# RP2350 register map
Vendor: Raspberry Pi; File version: 0.1
CPU: CM33 r1p0, little endian, MPU, FPU, VTOR, 4 interrupt priority bits, 54 interrupts, 8 SAU regions
Registers are 32-bit, read-write, reset 0x0 unless marked. A register's access mark holds for its fields unless they carry their own. Offsets are from the block's base; [hi:lo] are bit positions.

## ACCESSCTRL_APBS (part 2 of 2) — Hardware access control registers
Base 0x40060000
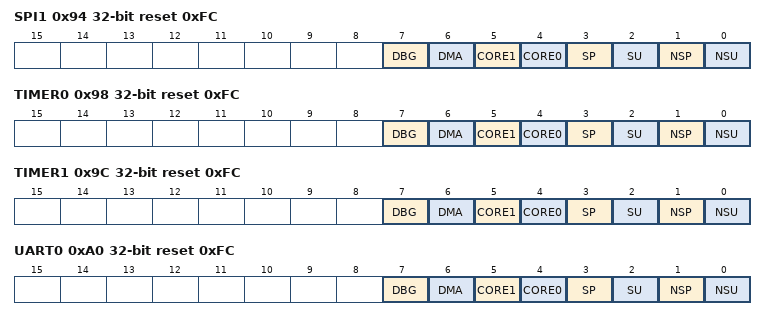
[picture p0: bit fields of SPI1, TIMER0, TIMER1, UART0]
0x94 SPI1 reset 0xFC — Control whether debugger, DMA, core 0 and core 1 can access SPI1, and at what security/privilege levels they can do so. . Defaults to Secure access from any master. . This register is writable only from a Secure, Privileged processor or debugger, with the exception of the NSU bit, which becomes NonSecure-Privileged-writable when the NSP bit is set.
  [7] DBG — If 1, SPI1 can be accessed by the debugger, at security/privilege levels permitted by SP/NSP/SU/NSU in this register.
  [6] DMA — If 1, SPI1 can be accessed by the DMA, at security/privilege levels permitted by SP/NSP/SU/NSU in this register.
  [5] CORE1 — If 1, SPI1 can be accessed by core 1, at security/privilege levels permitted by SP/NSP/SU/NSU in this register.
  [4] CORE0 — If 1, SPI1 can be accessed by core 0, at security/privilege levels permitted by SP/NSP/SU/NSU in this register.
  [3] SP — If 1, SPI1 can be accessed from a Secure, Privileged context.
  [2] SU — If 1, and SP is also set, SPI1 can be accessed from a Secure, Unprivileged context.
  [1] NSP — If 1, SPI1 can be accessed from a NonSecure, Privileged context.
  [0] NSU — If 1, and NSP is also set, SPI1 can be accessed from a NonSecure, Unprivileged context. . This bit is writable from a NonSecure, Privileged context, if and only if the NSP bit is set.
0x98 TIMER0 reset 0xFC — Control whether debugger, DMA, core 0 and core 1 can access TIMER0, and at what security/privilege levels they can do so. . Defaults to Secure access from any master. . This register is writable only from a Secure, Privileged processor or debugger, with the exception of the NSU bit, which becomes NonSecure-Privileged-writable when the NSP bit is set.
  [7] DBG — If 1, TIMER0 can be accessed by the debugger, at security/privilege levels permitted by SP/NSP/SU/NSU in this register.
  [6] DMA — If 1, TIMER0 can be accessed by the DMA, at security/privilege levels permitted by SP/NSP/SU/NSU in this register.
  [5] CORE1 — If 1, TIMER0 can be accessed by core 1, at security/privilege levels permitted by SP/NSP/SU/NSU in this register.
  [4] CORE0 — If 1, TIMER0 can be accessed by core 0, at security/privilege levels permitted by SP/NSP/SU/NSU in this register.
  [3] SP — If 1, TIMER0 can be accessed from a Secure, Privileged context.
  [2] SU — If 1, and SP is also set, TIMER0 can be accessed from a Secure, Unprivileged context.
  [1] NSP — If 1, TIMER0 can be accessed from a NonSecure, Privileged context.
  [0] NSU — If 1, and NSP is also set, TIMER0 can be accessed from a NonSecure, Unprivileged context. . This bit is writable from a NonSecure, Privileged context, if and only if the NSP bit is set.
0x9C TIMER1 reset 0xFC — Control whether debugger, DMA, core 0 and core 1 can access TIMER1, and at what security/privilege levels they can do so. . Defaults to Secure access from any master. . This register is writable only from a Secure, Privileged processor or debugger, with the exception of the NSU bit, which becomes NonSecure-Privileged-writable when the NSP bit is set.
  [7] DBG — If 1, TIMER1 can be accessed by the debugger, at security/privilege levels permitted by SP/NSP/SU/NSU in this register.
  [6] DMA — If 1, TIMER1 can be accessed by the DMA, at security/privilege levels permitted by SP/NSP/SU/NSU in this register.
  [5] CORE1 — If 1, TIMER1 can be accessed by core 1, at security/privilege levels permitted by SP/NSP/SU/NSU in this register.
  [4] CORE0 — If 1, TIMER1 can be accessed by core 0, at security/privilege levels permitted by SP/NSP/SU/NSU in this register.
  [3] SP — If 1, TIMER1 can be accessed from a Secure, Privileged context.
  [2] SU — If 1, and SP is also set, TIMER1 can be accessed from a Secure, Unprivileged context.
  [1] NSP — If 1, TIMER1 can be accessed from a NonSecure, Privileged context.
  [0] NSU — If 1, and NSP is also set, TIMER1 can be accessed from a NonSecure, Unprivileged context. . This bit is writable from a NonSecure, Privileged context, if and only if the NSP bit is set.
0xA0 UART0 reset 0xFC — Control whether debugger, DMA, core 0 and core 1 can access UART0, and at what security/privilege levels they can do so. . Defaults to Secure access from any master. . This register is writable only from a Secure, Privileged processor or debugger, with the exception of the NSU bit, which becomes NonSecure-Privileged-writable when the NSP bit is set.
  [7] DBG — If 1, UART0 can be accessed by the debugger, at security/privilege levels permitted by SP/NSP/SU/NSU in this register.
  [6] DMA — If 1, UART0 can be accessed by the DMA, at security/privilege levels permitted by SP/NSP/SU/NSU in this register.
  [5] CORE1 — If 1, UART0 can be accessed by core 1, at security/privilege levels permitted by SP/NSP/SU/NSU in this register.
  [4] CORE0 — If 1, UART0 can be accessed by core 0, at security/privilege levels permitted by SP/NSP/SU/NSU in this register.
  [3] SP — If 1, UART0 can be accessed from a Secure, Privileged context.
  [2] SU — If 1, and SP is also set, UART0 can be accessed from a Secure, Unprivileged context.
  [1] NSP — If 1, UART0 can be accessed from a NonSecure, Privileged context.
  [0] NSU — If 1, and NSP is also set, UART0 can be accessed from a NonSecure, Unprivileged context. . This bit is writable from a NonSecure, Privileged context, if and only if the NSP bit is set.
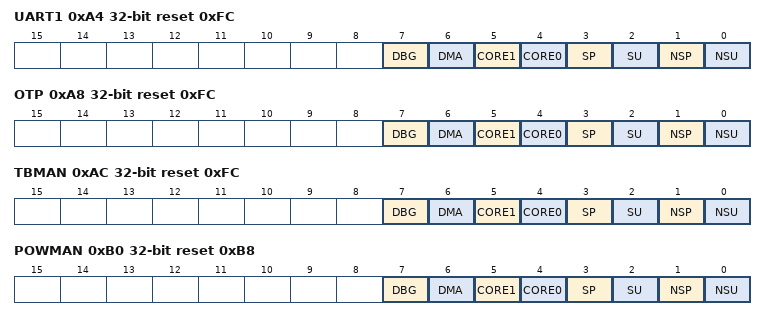
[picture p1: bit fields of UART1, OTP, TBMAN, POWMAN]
0xA4 UART1 reset 0xFC — Control whether debugger, DMA, core 0 and core 1 can access UART1, and at what security/privilege levels they can do so. . Defaults to Secure access from any master. . This register is writable only from a Secure, Privileged processor or debugger, with the exception of the NSU bit, which becomes NonSecure-Privileged-writable when the NSP bit is set.
  [7] DBG — If 1, UART1 can be accessed by the debugger, at security/privilege levels permitted by SP/NSP/SU/NSU in this register.
  [6] DMA — If 1, UART1 can be accessed by the DMA, at security/privilege levels permitted by SP/NSP/SU/NSU in this register.
  [5] CORE1 — If 1, UART1 can be accessed by core 1, at security/privilege levels permitted by SP/NSP/SU/NSU in this register.
  [4] CORE0 — If 1, UART1 can be accessed by core 0, at security/privilege levels permitted by SP/NSP/SU/NSU in this register.
  [3] SP — If 1, UART1 can be accessed from a Secure, Privileged context.
  [2] SU — If 1, and SP is also set, UART1 can be accessed from a Secure, Unprivileged context.
  [1] NSP — If 1, UART1 can be accessed from a NonSecure, Privileged context.
  [0] NSU — If 1, and NSP is also set, UART1 can be accessed from a NonSecure, Unprivileged context. . This bit is writable from a NonSecure, Privileged context, if and only if the NSP bit is set.
0xA8 OTP reset 0xFC — Control whether debugger, DMA, core 0 and core 1 can access OTP, and at what security/privilege levels they can do so. . Defaults to Secure access from any master. . This register is writable only from a Secure, Privileged processor or debugger, with the exception of the NSU bit, which becomes NonSecure-Privileged-writable when the NSP bit is set.
  [7] DBG — If 1, OTP can be accessed by the debugger, at security/privilege levels permitted by SP/NSP/SU/NSU in this register.
  [6] DMA — If 1, OTP can be accessed by the DMA, at security/privilege levels permitted by SP/NSP/SU/NSU in this register.
  [5] CORE1 — If 1, OTP can be accessed by core 1, at security/privilege levels permitted by SP/NSP/SU/NSU in this register.
  [4] CORE0 — If 1, OTP can be accessed by core 0, at security/privilege levels permitted by SP/NSP/SU/NSU in this register.
  [3] SP — If 1, OTP can be accessed from a Secure, Privileged context.
  [2] SU — If 1, and SP is also set, OTP can be accessed from a Secure, Unprivileged context.
  [1] NSP — If 1, OTP can be accessed from a NonSecure, Privileged context.
  [0] NSU — If 1, and NSP is also set, OTP can be accessed from a NonSecure, Unprivileged context. . This bit is writable from a NonSecure, Privileged context, if and only if the NSP bit is set.
0xAC TBMAN reset 0xFC — Control whether debugger, DMA, core 0 and core 1 can access TBMAN, and at what security/privilege levels they can do so. . Defaults to Secure access from any master. . This register is writable only from a Secure, Privileged processor or debugger, with the exception of the NSU bit, which becomes NonSecure-Privileged-writable when the NSP bit is set.
  [7] DBG — If 1, TBMAN can be accessed by the debugger, at security/privilege levels permitted by SP/NSP/SU/NSU in this register.
  [6] DMA — If 1, TBMAN can be accessed by the DMA, at security/privilege levels permitted by SP/NSP/SU/NSU in this register.
  [5] CORE1 — If 1, TBMAN can be accessed by core 1, at security/privilege levels permitted by SP/NSP/SU/NSU in this register.
  [4] CORE0 — If 1, TBMAN can be accessed by core 0, at security/privilege levels permitted by SP/NSP/SU/NSU in this register.
  [3] SP — If 1, TBMAN can be accessed from a Secure, Privileged context.
  [2] SU — If 1, and SP is also set, TBMAN can be accessed from a Secure, Unprivileged context.
  [1] NSP — If 1, TBMAN can be accessed from a NonSecure, Privileged context.
  [0] NSU — If 1, and NSP is also set, TBMAN can be accessed from a NonSecure, Unprivileged context. . This bit is writable from a NonSecure, Privileged context, if and only if the NSP bit is set.
0xB0 POWMAN reset 0xB8 — Control whether debugger, DMA, core 0 and core 1 can access POWMAN, and at what security/privilege levels they can do so. . Defaults to Secure, Privileged processor or debug access only. . This register is writable only from a Secure, Privileged processor or debugger, with the exception of the NSU bit, which becomes NonSecure-Privileged-writable when the NSP bit is set.
  [7] DBG — If 1, POWMAN can be accessed by the debugger, at security/privilege levels permitted by SP/NSP/SU/NSU in this register.
  [6] DMA — If 1, POWMAN can be accessed by the DMA, at security/privilege levels permitted by SP/NSP/SU/NSU in this register.
  [5] CORE1 — If 1, POWMAN can be accessed by core 1, at security/privilege levels permitted by SP/NSP/SU/NSU in this register.
  [4] CORE0 — If 1, POWMAN can be accessed by core 0, at security/privilege levels permitted by SP/NSP/SU/NSU in this register.
  [3] SP — If 1, POWMAN can be accessed from a Secure, Privileged context.
  [2] SU — If 1, and SP is also set, POWMAN can be accessed from a Secure, Unprivileged context.
  [1] NSP — If 1, POWMAN can be accessed from a NonSecure, Privileged context.
  [0] NSU — If 1, and NSP is also set, POWMAN can be accessed from a NonSecure, Unprivileged context. . This bit is writable from a NonSecure, Privileged context, if and only if the NSP bit is set.
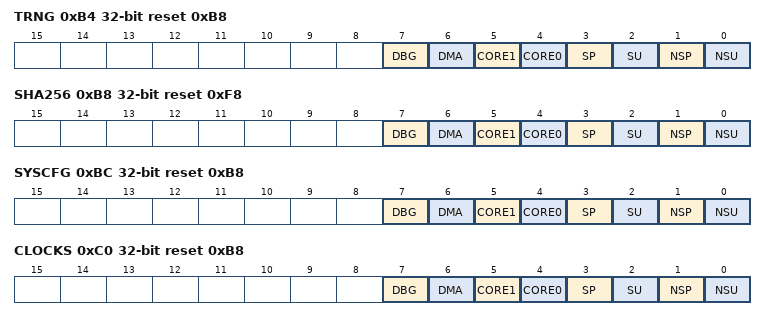
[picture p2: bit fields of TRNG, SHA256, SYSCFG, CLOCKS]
0xB4 TRNG reset 0xB8 — Control whether debugger, DMA, core 0 and core 1 can access TRNG, and at what security/privilege levels they can do so. . Defaults to Secure, Privileged processor or debug access only. . This register is writable only from a Secure, Privileged processor or debugger, with the exception of the NSU bit, which becomes NonSecure-Privileged-writable when the NSP bit is set.
  [7] DBG — If 1, TRNG can be accessed by the debugger, at security/privilege levels permitted by SP/NSP/SU/NSU in this register.
  [6] DMA — If 1, TRNG can be accessed by the DMA, at security/privilege levels permitted by SP/NSP/SU/NSU in this register.
  [5] CORE1 — If 1, TRNG can be accessed by core 1, at security/privilege levels permitted by SP/NSP/SU/NSU in this register.
  [4] CORE0 — If 1, TRNG can be accessed by core 0, at security/privilege levels permitted by SP/NSP/SU/NSU in this register.
  [3] SP — If 1, TRNG can be accessed from a Secure, Privileged context.
  [2] SU — If 1, and SP is also set, TRNG can be accessed from a Secure, Unprivileged context.
  [1] NSP — If 1, TRNG can be accessed from a NonSecure, Privileged context.
  [0] NSU — If 1, and NSP is also set, TRNG can be accessed from a NonSecure, Unprivileged context. . This bit is writable from a NonSecure, Privileged context, if and only if the NSP bit is set.
0xB8 SHA256 reset 0xF8 — Control whether debugger, DMA, core 0 and core 1 can access SHA256, and at what security/privilege levels they can do so. . Defaults to Secure, Privileged access only. . This register is writable only from a Secure, Privileged processor or debugger, with the exception of the NSU bit, which becomes NonSecure-Privileged-writable when the NSP bit is set.
  [7] DBG — If 1, SHA256 can be accessed by the debugger, at security/privilege levels permitted by SP/NSP/SU/NSU in this register.
  [6] DMA — If 1, SHA256 can be accessed by the DMA, at security/privilege levels permitted by SP/NSP/SU/NSU in this register.
  [5] CORE1 — If 1, SHA256 can be accessed by core 1, at security/privilege levels permitted by SP/NSP/SU/NSU in this register.
  [4] CORE0 — If 1, SHA256 can be accessed by core 0, at security/privilege levels permitted by SP/NSP/SU/NSU in this register.
  [3] SP — If 1, SHA256 can be accessed from a Secure, Privileged context.
  [2] SU — If 1, and SP is also set, SHA256 can be accessed from a Secure, Unprivileged context.
  [1] NSP — If 1, SHA256 can be accessed from a NonSecure, Privileged context.
  [0] NSU — If 1, and NSP is also set, SHA256 can be accessed from a NonSecure, Unprivileged context. . This bit is writable from a NonSecure, Privileged context, if and only if the NSP bit is set.
0xBC SYSCFG reset 0xB8 — Control whether debugger, DMA, core 0 and core 1 can access SYSCFG, and at what security/privilege levels they can do so. . Defaults to Secure, Privileged processor or debug access only. . This register is writable only from a Secure, Privileged processor or debugger, with the exception of the NSU bit, which becomes NonSecure-Privileged-writable when the NSP bit is set.
  [7] DBG — If 1, SYSCFG can be accessed by the debugger, at security/privilege levels permitted by SP/NSP/SU/NSU in this register.
  [6] DMA — If 1, SYSCFG can be accessed by the DMA, at security/privilege levels permitted by SP/NSP/SU/NSU in this register.
  [5] CORE1 — If 1, SYSCFG can be accessed by core 1, at security/privilege levels permitted by SP/NSP/SU/NSU in this register.
  [4] CORE0 — If 1, SYSCFG can be accessed by core 0, at security/privilege levels permitted by SP/NSP/SU/NSU in this register.
  [3] SP — If 1, SYSCFG can be accessed from a Secure, Privileged context.
  [2] SU — If 1, and SP is also set, SYSCFG can be accessed from a Secure, Unprivileged context.
  [1] NSP — If 1, SYSCFG can be accessed from a NonSecure, Privileged context.
  [0] NSU — If 1, and NSP is also set, SYSCFG can be accessed from a NonSecure, Unprivileged context. . This bit is writable from a NonSecure, Privileged context, if and only if the NSP bit is set.
0xC0 CLOCKS reset 0xB8 — Control whether debugger, DMA, core 0 and core 1 can access CLOCKS_BANK_DEFAULT, and at what security/privilege levels they can do so. . Defaults to Secure, Privileged processor or debug access only. . This register is writable only from a Secure, Privileged processor or debugger, with the exception of the NSU bit, which becomes NonSecure-Privileged-writable when the NSP bit is set.
  [7] DBG — If 1, CLOCKS_BANK_DEFAULT can be accessed by the debugger, at security/privilege levels permitted by SP/NSP/SU/NSU in this register.
  [6] DMA — If 1, CLOCKS_BANK_DEFAULT can be accessed by the DMA, at security/privilege levels permitted by SP/NSP/SU/NSU in this register.
  [5] CORE1 — If 1, CLOCKS_BANK_DEFAULT can be accessed by core 1, at security/privilege levels permitted by SP/NSP/SU/NSU in this register.
  [4] CORE0 — If 1, CLOCKS_BANK_DEFAULT can be accessed by core 0, at security/privilege levels permitted by SP/NSP/SU/NSU in this register.
  [3] SP — If 1, CLOCKS_BANK_DEFAULT can be accessed from a Secure, Privileged context.
  [2] SU — If 1, and SP is also set, CLOCKS_BANK_DEFAULT can be accessed from a Secure, Unprivileged context.
  [1] NSP — If 1, CLOCKS_BANK_DEFAULT can be accessed from a NonSecure, Privileged context.
  [0] NSU — If 1, and NSP is also set, CLOCKS_BANK_DEFAULT can be accessed from a NonSecure, Unprivileged context. . This bit is writable from a NonSecure, Privileged context, if and only if the NSP bit is set.
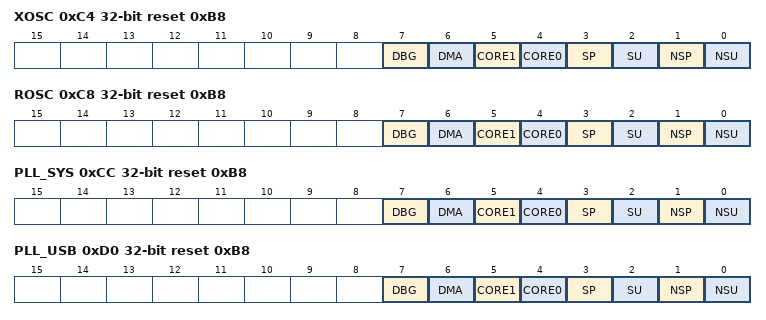
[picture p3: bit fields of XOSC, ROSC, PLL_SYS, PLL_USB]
0xC4 XOSC reset 0xB8 — Control whether debugger, DMA, core 0 and core 1 can access XOSC, and at what security/privilege levels they can do so. . Defaults to Secure, Privileged processor or debug access only. . This register is writable only from a Secure, Privileged processor or debugger, with the exception of the NSU bit, which becomes NonSecure-Privileged-writable when the NSP bit is set.
  [7] DBG — If 1, XOSC can be accessed by the debugger, at security/privilege levels permitted by SP/NSP/SU/NSU in this register.
  [6] DMA — If 1, XOSC can be accessed by the DMA, at security/privilege levels permitted by SP/NSP/SU/NSU in this register.
  [5] CORE1 — If 1, XOSC can be accessed by core 1, at security/privilege levels permitted by SP/NSP/SU/NSU in this register.
  [4] CORE0 — If 1, XOSC can be accessed by core 0, at security/privilege levels permitted by SP/NSP/SU/NSU in this register.
  [3] SP — If 1, XOSC can be accessed from a Secure, Privileged context.
  [2] SU — If 1, and SP is also set, XOSC can be accessed from a Secure, Unprivileged context.
  [1] NSP — If 1, XOSC can be accessed from a NonSecure, Privileged context.
  [0] NSU — If 1, and NSP is also set, XOSC can be accessed from a NonSecure, Unprivileged context. . This bit is writable from a NonSecure, Privileged context, if and only if the NSP bit is set.
0xC8 ROSC reset 0xB8 — Control whether debugger, DMA, core 0 and core 1 can access ROSC, and at what security/privilege levels they can do so. . Defaults to Secure, Privileged processor or debug access only. . This register is writable only from a Secure, Privileged processor or debugger, with the exception of the NSU bit, which becomes NonSecure-Privileged-writable when the NSP bit is set.
  [7] DBG — If 1, ROSC can be accessed by the debugger, at security/privilege levels permitted by SP/NSP/SU/NSU in this register.
  [6] DMA — If 1, ROSC can be accessed by the DMA, at security/privilege levels permitted by SP/NSP/SU/NSU in this register.
  [5] CORE1 — If 1, ROSC can be accessed by core 1, at security/privilege levels permitted by SP/NSP/SU/NSU in this register.
  [4] CORE0 — If 1, ROSC can be accessed by core 0, at security/privilege levels permitted by SP/NSP/SU/NSU in this register.
  [3] SP — If 1, ROSC can be accessed from a Secure, Privileged context.
  [2] SU — If 1, and SP is also set, ROSC can be accessed from a Secure, Unprivileged context.
  [1] NSP — If 1, ROSC can be accessed from a NonSecure, Privileged context.
  [0] NSU — If 1, and NSP is also set, ROSC can be accessed from a NonSecure, Unprivileged context. . This bit is writable from a NonSecure, Privileged context, if and only if the NSP bit is set.
0xCC PLL_SYS reset 0xB8 — Control whether debugger, DMA, core 0 and core 1 can access PLL_SYS, and at what security/privilege levels they can do so. . Defaults to Secure, Privileged processor or debug access only. . This register is writable only from a Secure, Privileged processor or debugger, with the exception of the NSU bit, which becomes NonSecure-Privileged-writable when the NSP bit is set.
  [7] DBG — If 1, PLL_SYS can be accessed by the debugger, at security/privilege levels permitted by SP/NSP/SU/NSU in this register.
  [6] DMA — If 1, PLL_SYS can be accessed by the DMA, at security/privilege levels permitted by SP/NSP/SU/NSU in this register.
  [5] CORE1 — If 1, PLL_SYS can be accessed by core 1, at security/privilege levels permitted by SP/NSP/SU/NSU in this register.
  [4] CORE0 — If 1, PLL_SYS can be accessed by core 0, at security/privilege levels permitted by SP/NSP/SU/NSU in this register.
  [3] SP — If 1, PLL_SYS can be accessed from a Secure, Privileged context.
  [2] SU — If 1, and SP is also set, PLL_SYS can be accessed from a Secure, Unprivileged context.
  [1] NSP — If 1, PLL_SYS can be accessed from a NonSecure, Privileged context.
  [0] NSU — If 1, and NSP is also set, PLL_SYS can be accessed from a NonSecure, Unprivileged context. . This bit is writable from a NonSecure, Privileged context, if and only if the NSP bit is set.
0xD0 PLL_USB reset 0xB8 — Control whether debugger, DMA, core 0 and core 1 can access PLL_USB, and at what security/privilege levels they can do so. . Defaults to Secure, Privileged processor or debug access only. . This register is writable only from a Secure, Privileged processor or debugger, with the exception of the NSU bit, which becomes NonSecure-Privileged-writable when the NSP bit is set.
  [7] DBG — If 1, PLL_USB can be accessed by the debugger, at security/privilege levels permitted by SP/NSP/SU/NSU in this register.
  [6] DMA — If 1, PLL_USB can be accessed by the DMA, at security/privilege levels permitted by SP/NSP/SU/NSU in this register.
  [5] CORE1 — If 1, PLL_USB can be accessed by core 1, at security/privilege levels permitted by SP/NSP/SU/NSU in this register.
  [4] CORE0 — If 1, PLL_USB can be accessed by core 0, at security/privilege levels permitted by SP/NSP/SU/NSU in this register.
  [3] SP — If 1, PLL_USB can be accessed from a Secure, Privileged context.
  [2] SU — If 1, and SP is also set, PLL_USB can be accessed from a Secure, Unprivileged context.
  [1] NSP — If 1, PLL_USB can be accessed from a NonSecure, Privileged context.
  [0] NSU — If 1, and NSP is also set, PLL_USB can be accessed from a NonSecure, Unprivileged context. . This bit is writable from a NonSecure, Privileged context, if and only if the NSP bit is set.
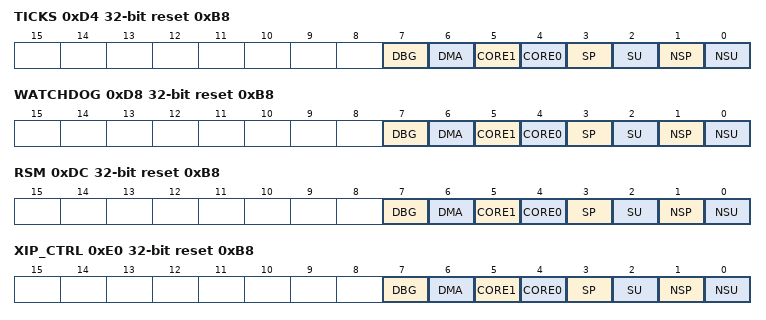
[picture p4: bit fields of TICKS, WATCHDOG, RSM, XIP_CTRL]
0xD4 TICKS reset 0xB8 — Control whether debugger, DMA, core 0 and core 1 can access TICKS, and at what security/privilege levels they can do so. . Defaults to Secure, Privileged processor or debug access only. . This register is writable only from a Secure, Privileged processor or debugger, with the exception of the NSU bit, which becomes NonSecure-Privileged-writable when the NSP bit is set.
  [7] DBG — If 1, TICKS can be accessed by the debugger, at security/privilege levels permitted by SP/NSP/SU/NSU in this register.
  [6] DMA — If 1, TICKS can be accessed by the DMA, at security/privilege levels permitted by SP/NSP/SU/NSU in this register.
  [5] CORE1 — If 1, TICKS can be accessed by core 1, at security/privilege levels permitted by SP/NSP/SU/NSU in this register.
  [4] CORE0 — If 1, TICKS can be accessed by core 0, at security/privilege levels permitted by SP/NSP/SU/NSU in this register.
  [3] SP — If 1, TICKS can be accessed from a Secure, Privileged context.
  [2] SU — If 1, and SP is also set, TICKS can be accessed from a Secure, Unprivileged context.
  [1] NSP — If 1, TICKS can be accessed from a NonSecure, Privileged context.
  [0] NSU — If 1, and NSP is also set, TICKS can be accessed from a NonSecure, Unprivileged context. . This bit is writable from a NonSecure, Privileged context, if and only if the NSP bit is set.
0xD8 WATCHDOG reset 0xB8 — Control whether debugger, DMA, core 0 and core 1 can access WATCHDOG, and at what security/privilege levels they can do so. . Defaults to Secure, Privileged processor or debug access only. . This register is writable only from a Secure, Privileged processor or debugger, with the exception of the NSU bit, which becomes NonSecure-Privileged-writable when the NSP bit is set.
  [7] DBG — If 1, WATCHDOG can be accessed by the debugger, at security/privilege levels permitted by SP/NSP/SU/NSU in this register.
  [6] DMA — If 1, WATCHDOG can be accessed by the DMA, at security/privilege levels permitted by SP/NSP/SU/NSU in this register.
  [5] CORE1 — If 1, WATCHDOG can be accessed by core 1, at security/privilege levels permitted by SP/NSP/SU/NSU in this register.
  [4] CORE0 — If 1, WATCHDOG can be accessed by core 0, at security/privilege levels permitted by SP/NSP/SU/NSU in this register.
  [3] SP — If 1, WATCHDOG can be accessed from a Secure, Privileged context.
  [2] SU — If 1, and SP is also set, WATCHDOG can be accessed from a Secure, Unprivileged context.
  [1] NSP — If 1, WATCHDOG can be accessed from a NonSecure, Privileged context.
  [0] NSU — If 1, and NSP is also set, WATCHDOG can be accessed from a NonSecure, Unprivileged context. . This bit is writable from a NonSecure, Privileged context, if and only if the NSP bit is set.
0xDC RSM reset 0xB8 — Control whether debugger, DMA, core 0 and core 1 can access RSM, and at what security/privilege levels they can do so. . Defaults to Secure, Privileged processor or debug access only. . This register is writable only from a Secure, Privileged processor or debugger, with the exception of the NSU bit, which becomes NonSecure-Privileged-writable when the NSP bit is set.
  [7] DBG — If 1, RSM can be accessed by the debugger, at security/privilege levels permitted by SP/NSP/SU/NSU in this register.
  [6] DMA — If 1, RSM can be accessed by the DMA, at security/privilege levels permitted by SP/NSP/SU/NSU in this register.
  [5] CORE1 — If 1, RSM can be accessed by core 1, at security/privilege levels permitted by SP/NSP/SU/NSU in this register.
  [4] CORE0 — If 1, RSM can be accessed by core 0, at security/privilege levels permitted by SP/NSP/SU/NSU in this register.
  [3] SP — If 1, RSM can be accessed from a Secure, Privileged context.
  [2] SU — If 1, and SP is also set, RSM can be accessed from a Secure, Unprivileged context.
  [1] NSP — If 1, RSM can be accessed from a NonSecure, Privileged context.
  [0] NSU — If 1, and NSP is also set, RSM can be accessed from a NonSecure, Unprivileged context. . This bit is writable from a NonSecure, Privileged context, if and only if the NSP bit is set.
0xE0 XIP_CTRL reset 0xB8 — Control whether debugger, DMA, core 0 and core 1 can access XIP_CTRL, and at what security/privilege levels they can do so. . Defaults to Secure, Privileged processor or debug access only. . This register is writable only from a Secure, Privileged processor or debugger, with the exception of the NSU bit, which becomes NonSecure-Privileged-writable when the NSP bit is set.
  [7] DBG — If 1, XIP_CTRL can be accessed by the debugger, at security/privilege levels permitted by SP/NSP/SU/NSU in this register.
  [6] DMA — If 1, XIP_CTRL can be accessed by the DMA, at security/privilege levels permitted by SP/NSP/SU/NSU in this register.
  [5] CORE1 — If 1, XIP_CTRL can be accessed by core 1, at security/privilege levels permitted by SP/NSP/SU/NSU in this register.
  [4] CORE0 — If 1, XIP_CTRL can be accessed by core 0, at security/privilege levels permitted by SP/NSP/SU/NSU in this register.
  [3] SP — If 1, XIP_CTRL can be accessed from a Secure, Privileged context.
  [2] SU — If 1, and SP is also set, XIP_CTRL can be accessed from a Secure, Unprivileged context.
  [1] NSP — If 1, XIP_CTRL can be accessed from a NonSecure, Privileged context.
  [0] NSU — If 1, and NSP is also set, XIP_CTRL can be accessed from a NonSecure, Unprivileged context. . This bit is writable from a NonSecure, Privileged context, if and only if the NSP bit is set.
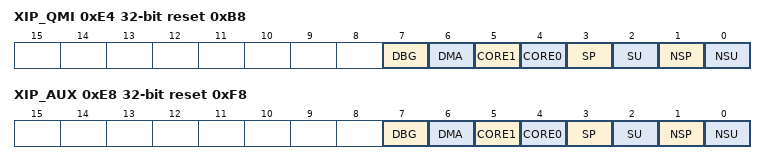
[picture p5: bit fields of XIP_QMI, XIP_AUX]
0xE4 XIP_QMI reset 0xB8 — Control whether debugger, DMA, core 0 and core 1 can access XIP_QMI, and at what security/privilege levels they can do so. . Defaults to Secure, Privileged processor or debug access only. . This register is writable only from a Secure, Privileged processor or debugger, with the exception of the NSU bit, which becomes NonSecure-Privileged-writable when the NSP bit is set.
  [7] DBG — If 1, XIP_QMI can be accessed by the debugger, at security/privilege levels permitted by SP/NSP/SU/NSU in this register.
  [6] DMA — If 1, XIP_QMI can be accessed by the DMA, at security/privilege levels permitted by SP/NSP/SU/NSU in this register.
  [5] CORE1 — If 1, XIP_QMI can be accessed by core 1, at security/privilege levels permitted by SP/NSP/SU/NSU in this register.
  [4] CORE0 — If 1, XIP_QMI can be accessed by core 0, at security/privilege levels permitted by SP/NSP/SU/NSU in this register.
  [3] SP — If 1, XIP_QMI can be accessed from a Secure, Privileged context.
  [2] SU — If 1, and SP is also set, XIP_QMI can be accessed from a Secure, Unprivileged context.
  [1] NSP — If 1, XIP_QMI can be accessed from a NonSecure, Privileged context.
  [0] NSU — If 1, and NSP is also set, XIP_QMI can be accessed from a NonSecure, Unprivileged context. . This bit is writable from a NonSecure, Privileged context, if and only if the NSP bit is set.
0xE8 XIP_AUX reset 0xF8 — Control whether debugger, DMA, core 0 and core 1 can access XIP_AUX, and at what security/privilege levels they can do so. . Defaults to Secure, Privileged access only. . This register is writable only from a Secure, Privileged processor or debugger, with the exception of the NSU bit, which becomes NonSecure-Privileged-writable when the NSP bit is set.
  [7] DBG — If 1, XIP_AUX can be accessed by the debugger, at security/privilege levels permitted by SP/NSP/SU/NSU in this register.
  [6] DMA — If 1, XIP_AUX can be accessed by the DMA, at security/privilege levels permitted by SP/NSP/SU/NSU in this register.
  [5] CORE1 — If 1, XIP_AUX can be accessed by core 1, at security/privilege levels permitted by SP/NSP/SU/NSU in this register.
  [4] CORE0 — If 1, XIP_AUX can be accessed by core 0, at security/privilege levels permitted by SP/NSP/SU/NSU in this register.
  [3] SP — If 1, XIP_AUX can be accessed from a Secure, Privileged context.
  [2] SU — If 1, and SP is also set, XIP_AUX can be accessed from a Secure, Unprivileged context.
  [1] NSP — If 1, XIP_AUX can be accessed from a NonSecure, Privileged context.
  [0] NSU — If 1, and NSP is also set, XIP_AUX can be accessed from a NonSecure, Unprivileged context. . This bit is writable from a NonSecure, Privileged context, if and only if the NSP bit is set.
